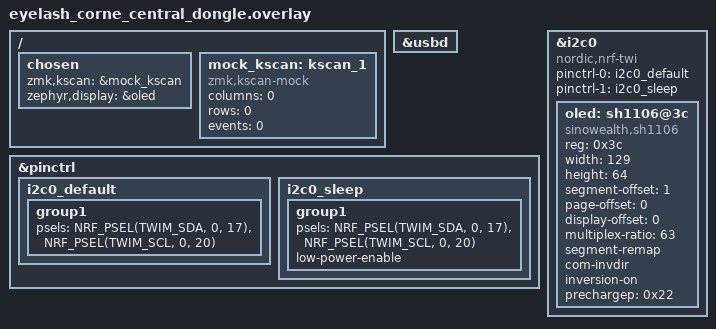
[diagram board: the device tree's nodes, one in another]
/*
 *
 * Copyright (c) 2021 Darryl deHaan
 * SPDX-License-Identifier: MIT
 *
 */

#include "../../../config/eyelash_corne_info.dtsi"

/ {
    chosen {
        /*
         * Dongle/central 本体没有真实矩阵，
         * 所以使用 mock_kscan。
         */
        zmk,kscan = &mock_kscan;

        /*
         * Dongle 上的 OLED 显示屏。
         */
        zephyr,display = &oled;
    };

    mock_kscan: kscan_1 {
        compatible = "zmk,kscan-mock";
        columns = <0>;
        rows = <0>;
        events = <0>;
    };
};

/*
 * Dongle 作为 USB central，一般需要启用 USB。
 * 如果 nice_nano_v2 的 board 已经启用了，这段保留也通常没问题。
 */
zephyr_udc0: &usbd {
    status = "okay";
};

&pinctrl {
    i2c0_default: i2c0_default {
        group1 {
            psels = <NRF_PSEL(TWIM_SDA, 0, 17)>,
                    <NRF_PSEL(TWIM_SCL, 0, 20)>;
        };
    };

    i2c0_sleep: i2c0_sleep {
        group1 {
            psels = <NRF_PSEL(TWIM_SDA, 0, 17)>,
                    <NRF_PSEL(TWIM_SCL, 0, 20)>;
            low-power-enable;
        };
    };
};

&i2c0 {
    status = "okay";
    compatible = "nordic,nrf-twi";
    pinctrl-0 = <&i2c0_default>;
    pinctrl-1 = <&i2c0_sleep>;
    pinctrl-names = "default", "sleep";

    oled: sh1106@3c {
        compatible = "sinowealth,sh1106";
        reg = <0x3c>;

        width = <129>;
        height = <64>;

        segment-offset = <1>;
        page-offset = <0>;
        display-offset = <0>;
        multiplex-ratio = <63>;

        segment-remap;
        com-invdir;
        inversion-on;

        prechargep = <0x22>;
    };
};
